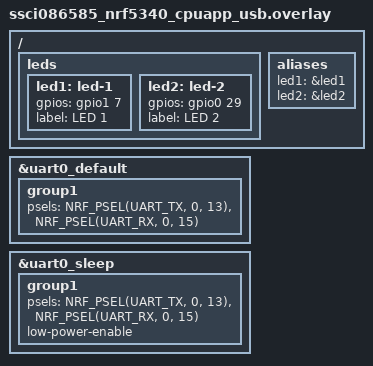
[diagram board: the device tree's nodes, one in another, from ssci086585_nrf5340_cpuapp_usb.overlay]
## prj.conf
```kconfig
#
# Copyright (c) 2016 Intel Corporation
#
# SPDX-License-Identifier: Apache-2.0
#

CONFIG_GPIO=y
# STEP 2 - Enable the serial driver in asynchronous mode
CONFIG_SERIAL=y
CONFIG_UART_ASYNC_API=y

# CONFIG_USB_CDC_ACM sets CONFIG_UART_INTERRUPT_DRIVEN=y.
# This will automatically disable the UART ASYNC API.
CONFIG_UART_0_INTERRUPT_DRIVEN=n
```

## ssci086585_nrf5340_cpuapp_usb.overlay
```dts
// To get started, press Ctrl+Space to bring up the completion menu and view the available nodes.

// You can also use the buttons in the sidebar to perform actions on nodes.
// Actions currently available include:

// * Enabling / disabling the node
// * Adding the bus to a bus
// * Removing the node
// * Connecting ADC channels

// For more help, browse the DeviceTree documentation at https://docs.zephyrproject.org/latest/guides/dts/index.html
// You can also visit the nRF DeviceTree extension documentation at https://docs.nordicsemi.com/bundle/nrf-connect-vscode/page/guides/ncs_configure_app.html#devicetree-support-in-the-extension

/ {
	leds {
		led1: led-1 {
			gpios = <&gpio1 7 0>;
			label = "LED 1";
		};

		led2: led-2 {
			gpios = <&gpio0 29 0>;
			label = "LED 2";
		};
	};

	aliases {
		led1 = &led1;
		led2 = &led2;
	};
};

/delete-node/ &{/pin-controller/qspi_default/group1/};
/delete-node/ &{/pin-controller/qspi_sleep/group1/};

&uart0_default {
	group1 {
		psels = <NRF_PSEL(UART_TX, 0, 13)>,
				<NRF_PSEL(UART_RX, 0, 15)>;
	};
};

&uart0_sleep {
	group1 {
		psels = <NRF_PSEL(UART_TX, 0, 13)>,
				<NRF_PSEL(UART_RX, 0, 15)>;
		low-power-enable;
	};
};
```

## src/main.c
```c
/*
 * Copyright (c) 2016 Intel Corporation
 *
 * SPDX-License-Identifier: Apache-2.0
 */

/* Controlling LEDs through UART. Press 1-3 on your keyboard to toggle LEDS 1-3 on your development kit */

#include <zephyr/kernel.h>
#include <zephyr/device.h>
#include <zephyr/devicetree.h>
#include <zephyr/drivers/gpio.h>
#include <zephyr/sys/printk.h>
#include <zephyr/usb/usb_device.h>
/* STEP 3 - Include the header file of the UART driver in main.c */
#include <zephyr/drivers/uart.h>

/* 1000 msec = 1 sec */
#define SLEEP_TIME_MS   1000

/* STEP 10.1.1 - Define the size of the receive buffer */
#define RECEIVE_BUFF_SIZE 10

/* STEP 10.2 - Define the receiving timeout period */
#define RECEIVE_TIMEOUT 100

/* STEP 5.1 - Get the device pointers of the LEDs through gpio_dt_spec */
#if defined (CONFIG_BOARD_NRF7002DK_NRF5340_CPUAPP)|| defined (CONFIG_BOARD_NRF7002DK_NRF5340_CPUAPP_NS)
static const struct gpio_dt_spec led0 = GPIO_DT_SPEC_GET(DT_ALIAS(led0), gpios);
static const struct gpio_dt_spec led1 = GPIO_DT_SPEC_GET(DT_ALIAS(led1), gpios);
#else
static const struct gpio_dt_spec led0 = GPIO_DT_SPEC_GET(DT_ALIAS(led0), gpios);
static const struct gpio_dt_spec led1 = GPIO_DT_SPEC_GET(DT_ALIAS(led1), gpios);
static const struct gpio_dt_spec led2 = GPIO_DT_SPEC_GET(DT_ALIAS(led2), gpios);
#endif


/* STEP 4.1 - Get the device pointer of the UART hardware */
const struct device *uart= DEVICE_DT_GET(DT_NODELABEL(uart0));

/* STEP 9.1 - Define the transmission buffer, which is a buffer to hold the data to be sent over UART */
static uint8_t tx_buf[] =   {"nRF Connect SDK Fundamentals Course\n\r"
                             "Press 1-3 on your keyboard to toggle LEDS 1-3 on your development kit\n\r"};

/* STEP 10.1.2 - Define the receive buffer */
static uint8_t rx_buf[RECEIVE_BUFF_SIZE] = {0};

/* STEP 7 - Define the callback function for UART */
static void uart_cb(const struct device *dev, struct uart_event *evt, void *user_data)
{
	switch (evt->type) {

	case UART_RX_RDY:
	#if defined (CONFIG_BOARD_NRF7002DK_NRF5340_CPUAPP)|| defined (CONFIG_BOARD_NRF7002DK_NRF5340_CPUAPP_NS)
		if((evt->data.rx.len) == 1){

		if(evt->data.rx.buf[evt->data.rx.offset] == '1')
			gpio_pin_toggle_dt(&led0);
		else if (evt->data.rx.buf[evt->data.rx.offset] == '2')
			gpio_pin_toggle_dt(&led1);	
		}
	#else
	if((evt->data.rx.len) == 1){
		if(evt->data.rx.buf[evt->data.rx.offset] == '1')
			gpio_pin_toggle_dt(&led0);
		else if (evt->data.rx.buf[evt->data.rx.offset] == '2')
			gpio_pin_toggle_dt(&led1);
		else if (evt->data.rx.buf[evt->data.rx.offset] == '3')
			gpio_pin_toggle_dt(&led2);					
		}
#endif
	break;
	case UART_RX_DISABLED:
		uart_rx_enable(dev ,rx_buf,sizeof rx_buf,RECEIVE_TIMEOUT);
		break;
		
	default:
		break;
	}
}

int main(void)
{
	int ret;

	if (IS_ENABLED(CONFIG_USB_DEVICE_STACK)) {
		int ret = usb_enable(NULL);
		if (ret) {
			return -1;
		}
	}
	printk("Lesson 5 Exercise 1 start\r\n");

/* STEP 4.2 - Verify that the UART device is ready */ 
	if (!device_is_ready(uart)){
		printk("UART device not ready\r\n");
		return 1 ;
	}

/* STEP 5.2 - Verify that the LED devices are ready */
	if (!device_is_ready(led0.port)){
		printk("GPIO device is not ready\r\n");
		return 1;
	}

/* STEP 6 - Configure the GPIOs of the LEDs */
#if defined (CONFIG_BOARD_NRF7002DK_NRF5340_CPUAPP)|| defined (CONFIG_BOARD_NRF7002DK_NRF5340_CPUAPP_NS)
	ret = gpio_pin_configure_dt(&led0, GPIO_OUTPUT_ACTIVE);
	if (ret < 0) {
		return 1 ; 
	}
	ret = gpio_pin_configure_dt(&led1, GPIO_OUTPUT_ACTIVE);
	if (ret < 0) {
		return 1 ;
	}
#else
	ret = gpio_pin_configure_dt(&led0, GPIO_OUTPUT_ACTIVE);
	if (ret < 0) {
		printk("Fail: led0\r\n");
		return 1 ; 
	}
	ret = gpio_pin_configure_dt(&led1, GPIO_OUTPUT_ACTIVE);
	if (ret < 0) {
		printk("Fail: led1\r\n");
		return 1 ;
	}
	ret = gpio_pin_configure_dt(&led2, GPIO_OUTPUT_ACTIVE);
	if (ret < 0) {
		printk("Fail: led2\r\n");
		return 1 ;
	}
#endif

/* STEP 8 - Register the UART callback function */
	ret = uart_callback_set(uart, uart_cb, NULL);
	if (ret) {
		printk("Fail: uart_callback_set(err=%d)\r\n", ret);
		return 1;
	}

/* STEP 9.2 - Send the data over UART by calling uart_tx() */
	ret = uart_tx(uart, tx_buf, sizeof(tx_buf), SYS_FOREVER_US);
	if (ret) {
		printk("Fail: uart_tx(err=%d)\r\n", ret);
		return 1;
	}

/* STEP 10.3  - Start receiving by calling uart_rx_enable() and pass it the address of the receive  buffer */
	ret = uart_rx_enable(uart ,rx_buf,sizeof rx_buf,RECEIVE_TIMEOUT);
	if (ret) {
		printk("Fail: uart_rx_enable(err=%d)\r\n", ret);
		return 1;
	}

	while (1) {
		k_msleep(SLEEP_TIME_MS);
	}
}
```
